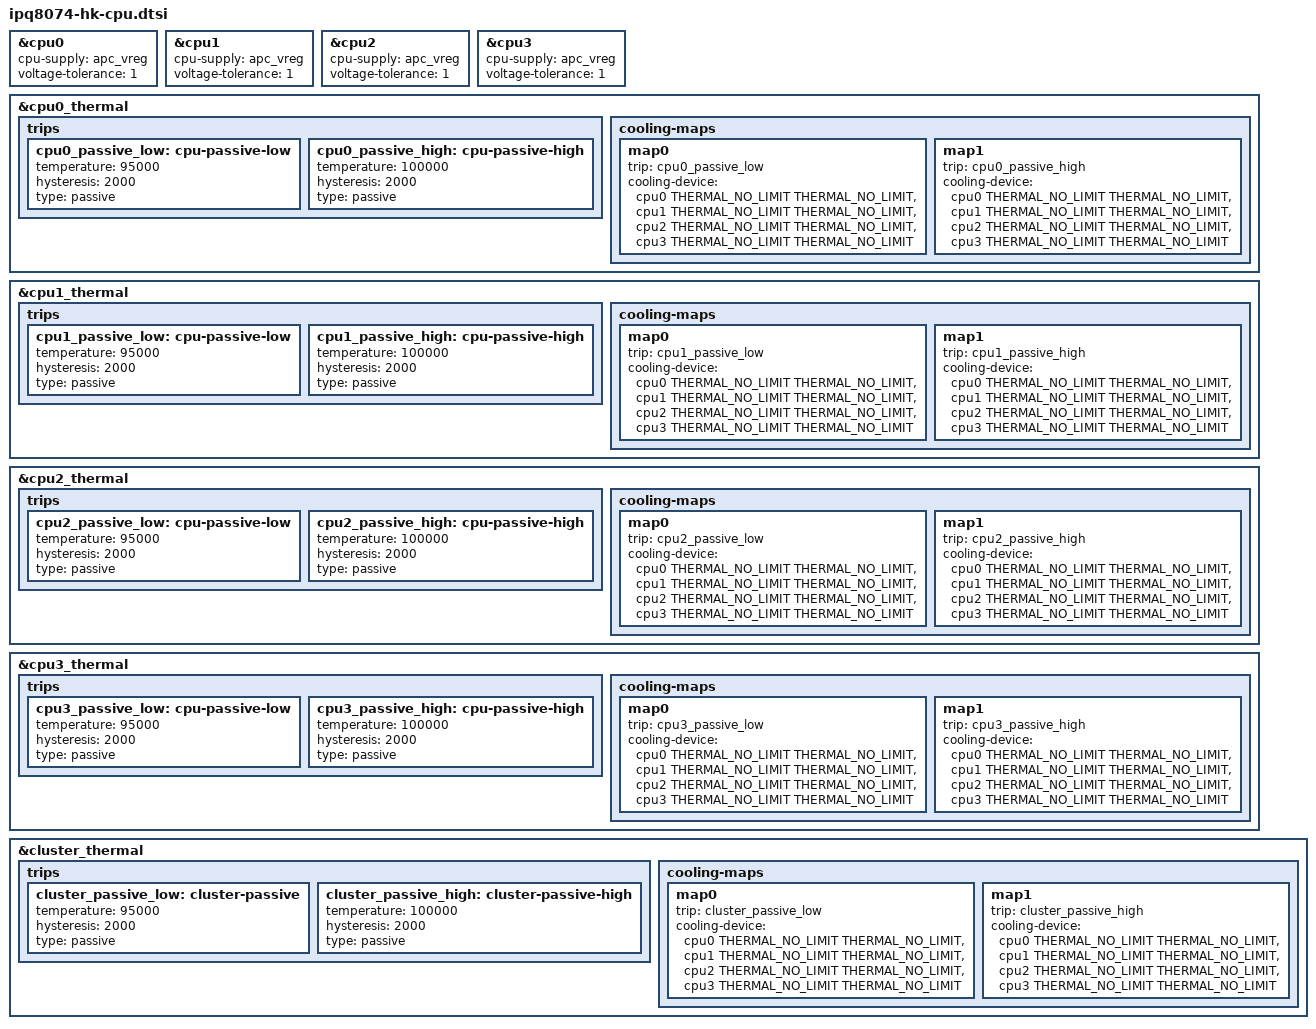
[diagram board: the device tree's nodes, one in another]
// SPDX-License-Identifier: GPL-2.0-only

#include <dt-bindings/thermal/thermal.h>
#include "ipq8074-cpr-regulator.dtsi"

&cpu0 {
	cpu-supply = <&apc_vreg>;
	voltage-tolerance = <1>;
};

&cpu1 {
	cpu-supply = <&apc_vreg>;
	voltage-tolerance = <1>;
};

&cpu2 {
	cpu-supply = <&apc_vreg>;
	voltage-tolerance = <1>;
};

&cpu3 {
	cpu-supply = <&apc_vreg>;
	voltage-tolerance = <1>;
};

&cpu0_thermal {
	trips {
		cpu0_passive_low: cpu-passive-low {
			temperature = <95000>;
			hysteresis = <2000>;
			type = "passive";
		};

		cpu0_passive_high: cpu-passive-high {
			temperature = <100000>;
			hysteresis = <2000>;
			type = "passive";
		};
	};

	cooling-maps {
		map0 {
			trip = <&cpu0_passive_low>;
			cooling-device = <&cpu0 THERMAL_NO_LIMIT THERMAL_NO_LIMIT>,
					 <&cpu1 THERMAL_NO_LIMIT THERMAL_NO_LIMIT>,
					 <&cpu2 THERMAL_NO_LIMIT THERMAL_NO_LIMIT>,
					 <&cpu3 THERMAL_NO_LIMIT THERMAL_NO_LIMIT>;
		};
		map1 {
			trip = <&cpu0_passive_high>;
			cooling-device = <&cpu0 THERMAL_NO_LIMIT THERMAL_NO_LIMIT>,
					 <&cpu1 THERMAL_NO_LIMIT THERMAL_NO_LIMIT>,
					 <&cpu2 THERMAL_NO_LIMIT THERMAL_NO_LIMIT>,
					 <&cpu3 THERMAL_NO_LIMIT THERMAL_NO_LIMIT>;
		};
	};
};

&cpu1_thermal {
	trips {
		cpu1_passive_low: cpu-passive-low {
			temperature = <95000>;
			hysteresis = <2000>;
			type = "passive";
		};

		cpu1_passive_high: cpu-passive-high {
			temperature = <100000>;
			hysteresis = <2000>;
			type = "passive";
		};
	};

	cooling-maps {
		map0 {
			trip = <&cpu1_passive_low>;
			cooling-device = <&cpu0 THERMAL_NO_LIMIT THERMAL_NO_LIMIT>,
					 <&cpu1 THERMAL_NO_LIMIT THERMAL_NO_LIMIT>,
					 <&cpu2 THERMAL_NO_LIMIT THERMAL_NO_LIMIT>,
					 <&cpu3 THERMAL_NO_LIMIT THERMAL_NO_LIMIT>;
		};
		map1 {
			trip = <&cpu1_passive_high>;
			cooling-device = <&cpu0 THERMAL_NO_LIMIT THERMAL_NO_LIMIT>,
					 <&cpu1 THERMAL_NO_LIMIT THERMAL_NO_LIMIT>,
					 <&cpu2 THERMAL_NO_LIMIT THERMAL_NO_LIMIT>,
					 <&cpu3 THERMAL_NO_LIMIT THERMAL_NO_LIMIT>;
		};
	};
};

&cpu2_thermal {
	trips {
		cpu2_passive_low: cpu-passive-low {
			temperature = <95000>;
			hysteresis = <2000>;
			type = "passive";
		};

		cpu2_passive_high: cpu-passive-high {
			temperature = <100000>;
			hysteresis = <2000>;
			type = "passive";
		};
	};

	cooling-maps {
		map0 {
			trip = <&cpu2_passive_low>;
			cooling-device = <&cpu0 THERMAL_NO_LIMIT THERMAL_NO_LIMIT>,
					 <&cpu1 THERMAL_NO_LIMIT THERMAL_NO_LIMIT>,
					 <&cpu2 THERMAL_NO_LIMIT THERMAL_NO_LIMIT>,
					 <&cpu3 THERMAL_NO_LIMIT THERMAL_NO_LIMIT>;
		};
		map1 {
			trip = <&cpu2_passive_high>;
			cooling-device = <&cpu0 THERMAL_NO_LIMIT THERMAL_NO_LIMIT>,
					 <&cpu1 THERMAL_NO_LIMIT THERMAL_NO_LIMIT>,
					 <&cpu2 THERMAL_NO_LIMIT THERMAL_NO_LIMIT>,
					 <&cpu3 THERMAL_NO_LIMIT THERMAL_NO_LIMIT>;
		};
	};
};

&cpu3_thermal {
	trips {
		cpu3_passive_low: cpu-passive-low {
			temperature = <95000>;
			hysteresis = <2000>;
			type = "passive";
		};

		cpu3_passive_high: cpu-passive-high {
			temperature = <100000>;
			hysteresis = <2000>;
			type = "passive";
		};
	};

	cooling-maps {
		map0 {
			trip = <&cpu3_passive_low>;
			cooling-device = <&cpu0 THERMAL_NO_LIMIT THERMAL_NO_LIMIT>,
					 <&cpu1 THERMAL_NO_LIMIT THERMAL_NO_LIMIT>,
					 <&cpu2 THERMAL_NO_LIMIT THERMAL_NO_LIMIT>,
					 <&cpu3 THERMAL_NO_LIMIT THERMAL_NO_LIMIT>;
		};
		map1 {
			trip = <&cpu3_passive_high>;
			cooling-device = <&cpu0 THERMAL_NO_LIMIT THERMAL_NO_LIMIT>,
					 <&cpu1 THERMAL_NO_LIMIT THERMAL_NO_LIMIT>,
					 <&cpu2 THERMAL_NO_LIMIT THERMAL_NO_LIMIT>,
					 <&cpu3 THERMAL_NO_LIMIT THERMAL_NO_LIMIT>;
		};
	};
};

&cluster_thermal {
	trips {
		cluster_passive_low: cluster-passive {
			temperature = <95000>;
			hysteresis = <2000>;
			type = "passive";
		};

		cluster_passive_high: cluster-passive-high {
			temperature = <100000>;
			hysteresis = <2000>;
			type = "passive";
		};
	};

	cooling-maps {
		map0 {
			trip = <&cluster_passive_low>;
			cooling-device = <&cpu0 THERMAL_NO_LIMIT THERMAL_NO_LIMIT>,
					 <&cpu1 THERMAL_NO_LIMIT THERMAL_NO_LIMIT>,
					 <&cpu2 THERMAL_NO_LIMIT THERMAL_NO_LIMIT>,
					 <&cpu3 THERMAL_NO_LIMIT THERMAL_NO_LIMIT>;
		};
		map1 {
			trip = <&cluster_passive_high>;
			cooling-device = <&cpu0 THERMAL_NO_LIMIT THERMAL_NO_LIMIT>,
					 <&cpu1 THERMAL_NO_LIMIT THERMAL_NO_LIMIT>,
					 <&cpu2 THERMAL_NO_LIMIT THERMAL_NO_LIMIT>,
					 <&cpu3 THERMAL_NO_LIMIT THERMAL_NO_LIMIT>;
		};
	};
};
